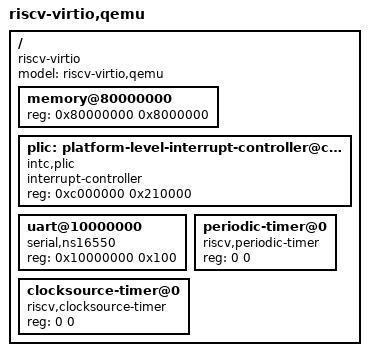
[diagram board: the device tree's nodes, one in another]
/*
 * Copyright (C) 2021 Nicolas Müller <nicolas.muller1@heig-vd.ch>
 *
 * This program is free software; you can redistribute it and/or modify
 * it under the terms of the GNU General Public License version 2 as
 * published by the Free Software Foundation.
 *
 * This program is distributed in the hope that it will be useful,
 * but WITHOUT ANY WARRANTY; without even the implied warranty of
 * MERCHANTABILITY or FITNESS FOR A PARTICULAR PURPOSE.  See the
 * GNU General Public License for more details.
 *
 * You should have received a copy of the GNU General Public License
 * along with this program; if not, write to the Free Software
 * Foundation, Inc., 51 Franklin St, Fifth Floor, Boston, MA  02110-1301  USA
 *
 */

/dts-v1/;

#include "skeleton.dtsi"

/ {
	compatible = "riscv-virtio";
	model = "riscv-virtio,qemu";

	memory@80000000 {
		device_type = "memory";
		reg = <0x80000000 0x8000000>;
	};
	
	plic:platform-level-interrupt-controller@c000000 {
		interrupt-controller;
		#interrupt-cells = <0x3>;
		
		reg = <0xc000000 0x210000>;
		compatible = "intc,plic";
		status = "ok";
	};

	uart@10000000 {
		/* _NMR_ interrupts = <0x0a>;
		 * interrupt-parent = <&plic>; */
		reg = <0x10000000 0x100>;
		compatible = "serial,ns16550";
		status = "ok";
	};
	
	periodic-timer@0 {
		compatible = "riscv,periodic-timer";
		reg = <0 0>;
		status = "ok";
	};
	
	clocksource-timer@0 {
		compatible = "riscv,clocksource-timer";
		reg = <0 0>;
		status = "ok";
	};
};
